# KM1M7CF16 register map
Vendor: Nuvoton Technology Corporation Japan; Series: KM1M7CF; File version: 1.0.3
KM1M7CF is a 32-bit microcontroller
CPU: CM7 r1p2, little endian, MPU, FPU, double-precision FPU, I-cache, D-cache, ITCM, DTCM, 4 interrupt priority bits
Registers are 32-bit, read-write, no defined reset value unless marked. A register's access mark holds for its fields unless they carry their own. Offsets are from the block's base; lines under a group give offsets from that group; [hi:lo] are bit positions; {n}, {i} and the like mark numbered series; 'fields as' and 'values as' point back to an identical list; <NAME> marks a mode.

## Memory map
0x40000000 SYTM size 0x2018 — Clock Generator
0x40003000 CKM size 0x184 — Clock Monitor
0x40004000 WDT size 0x18 — Watchdog Timer
0x40005000 MAP size 0x60 — RAM-ECC
0x40006000 INTC size 0x20016 — Interrupt Controller
0x40009000 CRC size 0x74 — CRC Calculation Circuit
0x4001C000 FL size 0xE8 — Flash Memory
0x4001C3C0 PLM size 0x8 — Product life-cycle manager
0x4001C3E4 FVC size 0x1C — Firmware version counter
0x40020000 PPWM size 0xF08 — Power Control PWM
0x40023000 ADC size 0x34004 — A/D Converter
0x40025000 MFA size 0x2FC — Multi Feedback Assist
0x40027000 DAC size 0xC2 — D/A Converter
0x40050000 SIF01 size 0xF15 — Serial Interface 0-1
0x40050200 SIF23456 size 0xD20 — Serial Interface 2-6
0x40050274 LIN size 0xD
0x40050300 SMBUS size 0xC21 — SMBus Interface
0x40051000 _16TM size 0x296 — 16-bit Timer
0x40052000 RTC size 0x36 — Real time clock
0x40054000 CMP size 0x5C — Comparator
0x40056000 PWRDET size 0x4 — Power Supply Voltage Detection
0x4005A000 PORT size 0xA60EA — I/O Port
0x40100100 NF size 0x48 — Noise Filter
0x40110000 CAN size 0x960 — CAN FD Cotroller
0x40200000 DMAC size 0x1F0C — DMA Controller
0x40202000 TRNG size 0x18
0x40300000 CRYPTO size 0x1000

## Interrupts
{n} G{n} (INTC) (n=0..15)
{n} G{n} (CMP) (n=16..27)
30 G30 (PWRDET)
31 G31 (SYTM)
32 G32 (SYTM)
34 G34 (SYTM)
35 G35 (ADC)
36 G36 (ADC)
37 G37 (ADC)
38 G38 (ADC)
39 G39 (ADC)
40 G40 (ADC)
41 G41 (ADC)
{n} G{n} (PPWM) (n=44..67)
{n} G{n} (_16TM) (n=93..106)
107 G107 (RTC)
108 G108 (RTC)
111 G111 (SIF01)
112 G112 (SIF01)
113 G113 (SIF01)
114 G114 (SIF01)
{n} G{n} (SIF23456) (n=115..122)
124 G124 (SIF23456)
125 G125 (SIF23456)
126 G126 (SMBUS)
127 G127 (SMBUS)
136 G136 (CAN)
137 G137 (CAN)
140 G140 (CAN)
{n} G{n} (DMAC) (n=144..154)
155 G155 (FL)
157 G157 (TRNG)
158 G158 (TRNG)
159 G159 (CRYPTO)

## CKM — Clock Monitor
Base 0x40003000
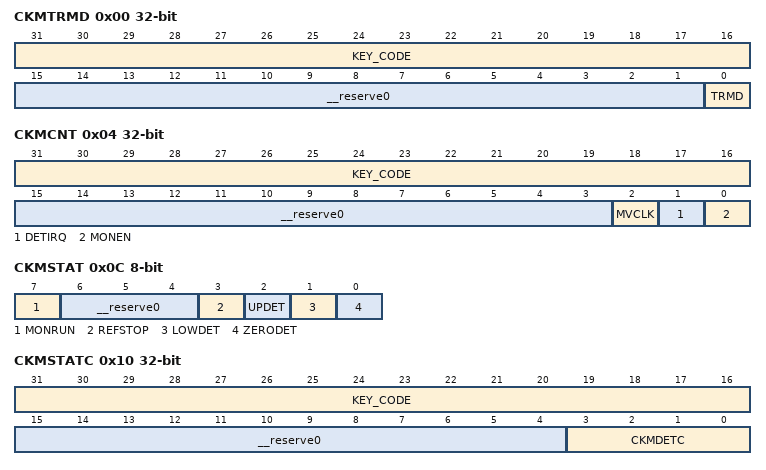
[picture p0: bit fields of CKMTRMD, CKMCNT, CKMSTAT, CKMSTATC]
0x00 CKMTRMD access per field — Clock Transition Mode Register
  [31:16] KEY_CODE rw — Register Key
  [15:1] __reserve0 ro — "0" is always read out.
  [0] TRMD rw — Status and control of the clock transition mode
0x04 CKMCNT access per field — Clock Monitoring Enable Register
  [31:16] KEY_CODE rw — Register Key
  [15:3] __reserve0 ro — "0" is always read out.
  [2] MVCLK rw — Selection of condition to enter clock transition mode
  [1] DETIRQ rw — Action at clock error detection
  [0] MONEN rw — Clock monitoring function enable
0x0C CKMSTAT 8-bit ro — Clock Monitoring Status Register
  [7] MONRUN — Clock monitoring function running status
  [6:4] __reserve0 — "0" is always read out.
  [3] REFSTOP — Clock error factor (reference clock stop)
  [2] UPDET — Clock error factor (upper frequency error)
  [1] LOWDET — Clock error factor (lower frequency error)
  [0] ZERODET — Clock error factor (target clock stop)
0x10 CKMSTATC access per field — Clock Monitoring Status Clear Register
  [31:16] KEY_CODE rw — Register Key
  [15:4] __reserve0 ro — "0" is always read out.
  [3:0] CKMDETC wo — Clear CKMSTAT
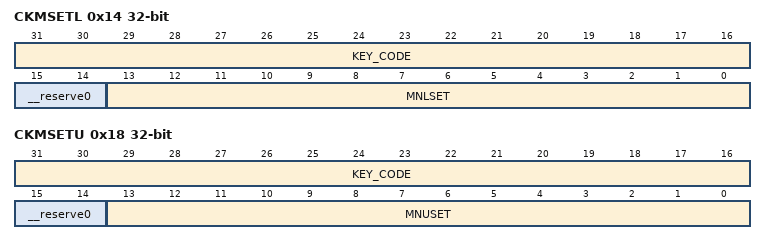
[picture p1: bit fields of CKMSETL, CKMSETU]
0x14 CKMSETL access per field — Clock Monitoring Frequency Lower Limit Setting Register
  [31:16] KEY_CODE rw — Register Key
  [15:14] __reserve0 ro — "0" is always read out.
  [13:0] MNLSET rw — Lower frequency limit setting for clock monitoring
0x18 CKMSETU access per field — Clock Monitoring Frequency Upper Limit Setting Register
  [31:16] KEY_CODE rw — Register Key
  [15:14] __reserve0 ro — "0" is always read out.
  [13:0] MNUSET rw — Upper frequency limit setting for clock monitoring
